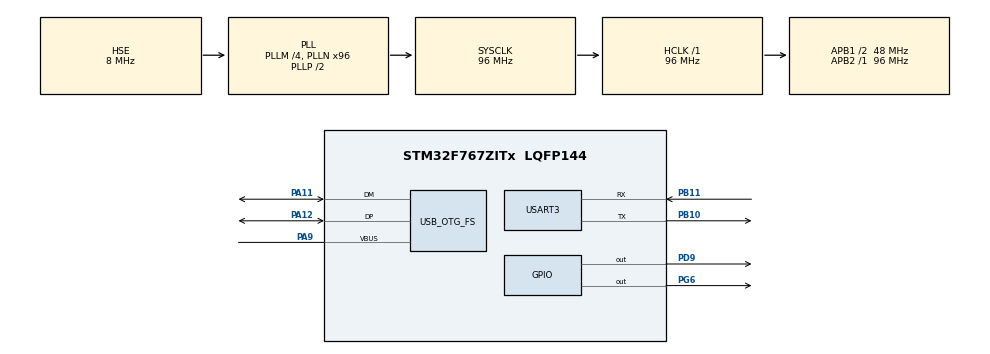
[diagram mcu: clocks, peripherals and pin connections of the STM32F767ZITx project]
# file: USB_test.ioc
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FATFS._MAX_SS=4096
Mcu.Family=STM32F7
Mcu.Name=STM32F767ZITx
Mcu.Package=LQFP144
NVIC.OTG_FS_IRQn=true\:0\:0\:false\:false\:true\:false\:true
NVIC.PriorityGroup=NVIC_PRIORITYGROUP_4
PA11.Mode=Host_Only
PA11.Signal=USB_OTG_FS_DM
PA12.Mode=Host_Only
PA12.Signal=USB_OTG_FS_DP
PA9.Mode=Activate_VBUS
PA9.Signal=USB_OTG_FS_VBUS
PB10.Mode=Asynchronous
PB10.Signal=USART3_TX
PB11.Mode=Asynchronous
PB11.Signal=USART3_RX
PD9.Signal=GPIO_Output
PG6.PinState=GPIO_PIN_SET
PG6.Signal=GPIO_Output
PH0/OSC_IN.Mode=HSE-External-Oscillator
PH0/OSC_IN.Signal=RCC_OSC_IN
PH1/OSC_OUT.Mode=HSE-External-Oscillator
PH1/OSC_OUT.Signal=RCC_OSC_OUT
ProjectManager.HeapSize=0x200
ProjectManager.StackSize=0x400
ProjectManager.TargetToolchain=STM32CubeIDE
RCC.48MHZClocksFreq_Value=24000000
RCC.AHBFreq_Value=96000000
RCC.APB1CLKDivider=RCC_HCLK_DIV2
RCC.APB1Freq_Value=48000000
RCC.APB1TimFreq_Value=96000000
RCC.APB2Freq_Value=96000000
RCC.APB2TimFreq_Value=96000000
RCC.CortexFreq_Value=96000000
RCC.HCLKFreq_Value=96000000
RCC.HSE_VALUE=8000000
RCC.HSI_VALUE=16000000
RCC.LSE_VALUE=32768
RCC.PLLM=4
RCC.PLLMUL=RCC_PLL_MUL9
RCC.PLLN=96
RCC.PLLQ=4
RCC.PRESCALERUSB=RCC_USBCLKSOURCE_PLL_DIV1_5
RCC.SYSCLKFreq_VALUE=96000000
RCC.SYSCLKSource=RCC_SYSCLKSOURCE_PLLCLK
RCC.SYSCLKSourceVirtual=RCC_SYSCLKSOURCE_PLLCLK
RCC.USBFreq_Value=48000000
RCC.VCOOutputFreq_Value=192000000
USART3.VirtualMode-Asynchronous=VM_ASYNC
USB_HOST.USBH_HandleTypeDef-MSC_FS=hUsbHostFS
USB_HOST.VirtualModeFS=Msc
USB_OTG_FS.VirtualMode=Host_Only
USB_OTG_FS.phy_itface=HCD_PHY_EMBEDDED
VP_FATFS_VS_USB.Mode=USB
VP_USB_HOST_VS_USB_HOST_MSC_FS.Mode=MSC_FS
board=NUCLEO-F767ZI

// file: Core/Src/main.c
/* USER CODE BEGIN Header */
/**
  ******************************************************************************
  * @file           : main.c
  * @brief          : Main program body
  ******************************************************************************
  * @attention
  *
  * <h2><center>&copy; Copyright (c) 2020 STMicroelectronics.
  * All rights reserved.</center></h2>
  *
  * This software component is licensed by ST under BSD 3-Clause license,
  * the "License"; You may not use this file except in compliance with the
  * License. You may obtain a copy of the License at:
  *                        opensource.org/licenses/BSD-3-Clause
  *
  ******************************************************************************
  */
/* USER CODE END Header */

#include "main.h"
#include "fatfs.h"
#include "usb_host.h"

/* USER CODE BEGIN Includes */
#include "File_Handling.h"
/* USER CODE END Includes */

UART_HandleTypeDef huart3;

/* USER CODE BEGIN PV */
unsigned long err_cnt;
/* USER CODE END PV */

void SystemClock_Config(void);
static void MX_GPIO_Init(void);
static void MX_USART3_UART_Init(void);
void MX_USB_HOST_Process(void);

int main(void)
{

  /* MCU Configuration--------------------------------------------------------*/

  /* Reset of all peripherals, Initializes the Flash interface and the Systick. */
  HAL_Init();

  /* Configure the system clock */
  SystemClock_Config();

  /* Initialize all configured peripherals */
  MX_GPIO_Init();
  MX_USART3_UART_Init();
  MX_FATFS_Init();
  MX_USB_HOST_Init();
  /* USER CODE BEGIN 2 */

  Send_Uart("begin usb app\n");
  /* USER CODE END 2 */

  /* Infinite loop */
  while (1)
  {
    MX_USB_HOST_Process();

  }
}

void SystemClock_Config(void)
{
  RCC_OscInitTypeDef RCC_OscInitStruct = {0};
  RCC_ClkInitTypeDef RCC_ClkInitStruct = {0};
  RCC_PeriphCLKInitTypeDef PeriphClkInitStruct = {0};

  /** Configure the main internal regulator output voltage
  */
  __HAL_RCC_PWR_CLK_ENABLE();
  __HAL_PWR_VOLTAGESCALING_CONFIG(PWR_REGULATOR_VOLTAGE_SCALE3);
  /** Initializes the CPU, AHB and APB busses clocks
  */
  RCC_OscInitStruct.OscillatorType = RCC_OSCILLATORTYPE_HSE;
  RCC_OscInitStruct.HSEState = RCC_HSE_ON;
  RCC_OscInitStruct.PLL.PLLState = RCC_PLL_ON;
  RCC_OscInitStruct.PLL.PLLSource = RCC_PLLSOURCE_HSE;
  RCC_OscInitStruct.PLL.PLLM = 4;
  RCC_OscInitStruct.PLL.PLLN = 96;
  RCC_OscInitStruct.PLL.PLLP = RCC_PLLP_DIV2;
  RCC_OscInitStruct.PLL.PLLQ = 4;
  if (HAL_RCC_OscConfig(&RCC_OscInitStruct) != HAL_OK)
  {
    Error_Handler();
  }
  /** Activate the Over-Drive mode
  */
  if (HAL_PWREx_EnableOverDrive() != HAL_OK)
  {
    Error_Handler();
  }
  /** Initializes the CPU, AHB and APB busses clocks
  */
  RCC_ClkInitStruct.ClockType = RCC_CLOCKTYPE_HCLK|RCC_CLOCKTYPE_SYSCLK
                              |RCC_CLOCKTYPE_PCLK1|RCC_CLOCKTYPE_PCLK2;
  RCC_ClkInitStruct.SYSCLKSource = RCC_SYSCLKSOURCE_PLLCLK;
  RCC_ClkInitStruct.AHBCLKDivider = RCC_SYSCLK_DIV1;
  RCC_ClkInitStruct.APB1CLKDivider = RCC_HCLK_DIV2;
  RCC_ClkInitStruct.APB2CLKDivider = RCC_HCLK_DIV1;

  if (HAL_RCC_ClockConfig(&RCC_ClkInitStruct, FLASH_LATENCY_3) != HAL_OK)
  {
    Error_Handler();
  }
  PeriphClkInitStruct.PeriphClockSelection = RCC_PERIPHCLK_USART3|RCC_PERIPHCLK_CLK48;
  PeriphClkInitStruct.Usart3ClockSelection = RCC_USART3CLKSOURCE_PCLK1;
  PeriphClkInitStruct.Clk48ClockSelection = RCC_CLK48SOURCE_PLL;
  if (HAL_RCCEx_PeriphCLKConfig(&PeriphClkInitStruct) != HAL_OK)
  {
    Error_Handler();
  }
}

static void MX_USART3_UART_Init(void)
{

  huart3.Instance = USART3;
  huart3.Init.BaudRate = 115200;
  huart3.Init.WordLength = UART_WORDLENGTH_8B;
  huart3.Init.StopBits = UART_STOPBITS_1;
  huart3.Init.Parity = UART_PARITY_NONE;
  huart3.Init.Mode = UART_MODE_TX_RX;
  huart3.Init.HwFlowCtl = UART_HWCONTROL_NONE;
  huart3.Init.OverSampling = UART_OVERSAMPLING_16;
  huart3.Init.OneBitSampling = UART_ONE_BIT_SAMPLE_DISABLE;
  huart3.AdvancedInit.AdvFeatureInit = UART_ADVFEATURE_NO_INIT;
  if (HAL_UART_Init(&huart3) != HAL_OK)
  {
    Error_Handler();
  }

}

static void MX_GPIO_Init(void)
{
  GPIO_InitTypeDef GPIO_InitStruct = {0};

  /* GPIO Ports Clock Enable */
  __HAL_RCC_GPIOH_CLK_ENABLE();
  __HAL_RCC_GPIOB_CLK_ENABLE();
  __HAL_RCC_GPIOD_CLK_ENABLE();
  __HAL_RCC_GPIOG_CLK_ENABLE();
  __HAL_RCC_GPIOA_CLK_ENABLE();

  /*Configure GPIO pin Output Level */
  HAL_GPIO_WritePin(GPIOD, GPIO_PIN_9, GPIO_PIN_RESET);

  /*Configure GPIO pin Output Level */
  HAL_GPIO_WritePin(GPIOG, GPIO_PIN_6, GPIO_PIN_SET);

  /*Configure GPIO pin : PD9 */
  GPIO_InitStruct.Pin = GPIO_PIN_9;
  GPIO_InitStruct.Mode = GPIO_MODE_OUTPUT_PP;
  GPIO_InitStruct.Pull = GPIO_NOPULL;
  GPIO_InitStruct.Speed = GPIO_SPEED_FREQ_LOW;
  HAL_GPIO_Init(GPIOD, &GPIO_InitStruct);

  /*Configure GPIO pin : PG6 */
  GPIO_InitStruct.Pin = GPIO_PIN_6;
  GPIO_InitStruct.Mode = GPIO_MODE_OUTPUT_PP;
  GPIO_InitStruct.Pull = GPIO_NOPULL;
  GPIO_InitStruct.Speed = GPIO_SPEED_FREQ_LOW;
  HAL_GPIO_Init(GPIOG, &GPIO_InitStruct);

}

void Error_Handler(void)
{
  /* USER CODE BEGIN Error_Handler_Debug */
  /* User can add his own implementation to report the HAL error return state */
   err_cnt++;
  /* USER CODE END Error_Handler_Debug */
}

/************************ (C) COPYRIGHT STMicroelectronics *****END OF FILE****/
